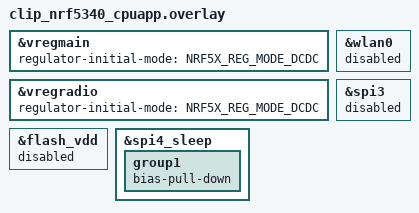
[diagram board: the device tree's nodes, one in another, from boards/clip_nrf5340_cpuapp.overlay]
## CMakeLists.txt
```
# SPDX-License-Identifier: Apache-2.0

cmake_minimum_required(VERSION 3.20.0)

find_package(Zephyr REQUIRED HINTS $ENV{ZEPHYR_BASE})

project(suspend_to_ram)

target_sources(app PRIVATE src/main.c)
```

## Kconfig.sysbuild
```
#
# SPDX-License-Identifier: Apache-2.0
#
# Sysbuild config — required for nRF5340 Bluetooth controller.
# Builds the cpunet child image with the BT HCI IPC firmware so the
# application core (cpuapp) can talk to the BLE controller over IPC.

source "${ZEPHYR_BASE}/share/sysbuild/Kconfig"

config NRF_DEFAULT_IPC_RADIO
	default y

config NETCORE_IPC_RADIO_BT_HCI_IPC
	default y
```

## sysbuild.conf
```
# SPDX-License-Identifier: Apache-2.0
#
# MCUboot sysbuild configuration
#
# Build: west build --build-dir build-<sample> --board clip/nrf5340/cpuapp samples/<sample>

# MCUboot bootloader
SB_CONFIG_BOOTLOADER_MCUBOOT=y

# External SPI flash for DFU secondary partition
SB_CONFIG_PM_EXTERNAL_FLASH_MCUBOOT_SECONDARY=y
SB_CONFIG_PM_OVERRIDE_EXTERNAL_DRIVER_CHECK=y

# Dual-image MCUboot (app + netcore)
SB_CONFIG_MCUBOOT_UPDATEABLE_IMAGES=2
SB_CONFIG_MCUBOOT_NRF53_MULTI_IMAGE_UPDATE=y
SB_CONFIG_NETCORE_APP_UPDATE=y

# Overwrite-only mode (no rollback)
SB_CONFIG_MCUBOOT_MODE_OVERWRITE_ONLY=y

# Network core IPC radio (required on nRF5340 dual-core)
SB_CONFIG_NETCORE_IPC_RADIO=y
SB_CONFIG_NETCORE_IPC_RADIO_BT_HCI_IPC=y

# Secure boot for network core
SB_CONFIG_SECURE_BOOT_NETCORE=y

# Signing key (must match the key used to build MCUboot on the device)
SB_CONFIG_BOOT_SIGNATURE_KEY_FILE="${APPLICATION_CONFIG_DIR}/sysbuild/root-rsa-2048.pem"
```

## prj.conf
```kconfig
# SPDX-License-Identifier: Apache-2.0
#
# PMIC + SoC suspend-to-RAM test for nRF5340 on reSpeaker Clip.
# No nRF7002 / WiFi stack (the wlan0 node is disabled in the overlay).
# BLE advertising is used as a suspend indicator.
# Builds under MCUboot like the other samples; the external SPI flash stays
# in the partition layout (mcuboot's secondary slot) but its driver/bus are
# disabled here and the rail is power-gated at runtime.

CONFIG_MAIN_STACK_SIZE=2048
CONFIG_HEAP_MEM_POOL_SIZE=0

# Power management
CONFIG_PM=y
CONFIG_PM_DEVICE=y
CONFIG_PM_DEVICE_RUNTIME=y
CONFIG_TICKLESS_KERNEL=y

# PMIC control (nPM1300) — rail power-gating
CONFIG_I2C=y
CONFIG_MFD=y
CONFIG_MFD_NPM13XX=y
CONFIG_REGULATOR=y
CONFIG_REGULATOR_NPM13XX=y

# Bluetooth Low Energy advertising (suspend indicator)
CONFIG_BT=y
CONFIG_BT_PERIPHERAL=y
CONFIG_BT_DEVICE_NAME="Clip"

# Indicator GPIO + console
CONFIG_GPIO=y
CONFIG_SERIAL=y
CONFIG_UART_CONSOLE=y
CONFIG_CONSOLE=y
CONFIG_LOG=y
CONFIG_LOG_DEFAULT_LEVEL=3

# SPI for SD card (SPI4)
CONFIG_SPI=y

# SD card + FAT filesystem
CONFIG_FILE_SYSTEM=y
CONFIG_FAT_FILESYSTEM_ELM=y
CONFIG_FS_FATFS_LFN=y
CONFIG_DISK_ACCESS=y
CONFIG_DISK_DRIVER_SDMMC=y

# Flash: keep the partition map (mcuboot slot layout) but no external SPI
# flash driver — the external flash bus/rail are disabled in the overlay.
CONFIG_FLASH=y
CONFIG_FLASH_MAP=y
CONFIG_SPI_NOR=n

# Disable unused reSpeaker Clip module defaults for this sample
CONFIG_OLED_DISPLAY=n
CONFIG_GPIO_BUTTON=n
CONFIG_SENSOR=n
CONFIG_INPUT=n
```

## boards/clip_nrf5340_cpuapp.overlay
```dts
/*
 * SPDX-License-Identifier: Apache-2.0
 *
 * Switch nRF5340 internal regulators from the SDK default LDO to DCDC.
 * The Clip board has 10µH inductors (L1, L2) wired for DCDC support.
 * Without this, suspend current is ~500-600 µA higher than the datasheet.
 *
 * Disable the nRF7002 WiFi node so its driver and the MPSL coexistence
 * service (which would otherwise keep HFXO running) are not pulled in.
 */

&vregmain {
	regulator-initial-mode = <NRF5X_REG_MODE_DCDC>;
};

&vregradio {
	regulator-initial-mode = <NRF5X_REG_MODE_DCDC>;
};

&wlan0 {
	status = "disabled";
};

/* Disable the external SPI flash bus and its power rail for the idle
 * current baseline. The external flash stays in the partition map (it is
 * mcuboot's secondary slot — mcuboot enables it in its own overlay), so do
 * NOT delete nordic,pm-ext-flash here or mcuboot fails to find its
 * secondary slot (PM_MCUBOOT_SECONDARY_ID undeclared). */
&spi3 {
	status = "disabled";
};

&flash_vdd {
	status = "disabled";
};

/*
 * Add pull-down to SPI4 sleep pinctrl so suspended pins don't float
 * and leak through the SD card's ESD diodes.
 */
&spi4_sleep {
	group1 {
		bias-pull-down;
	};
};
```

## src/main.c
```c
/*
 * SPDX-License-Identifier: Apache-2.0
 *
 * PM_STATE_SUSPEND_TO_RAM test for reSpeaker Clip (nRF5340) with the
 * peripheral rails turned off. No nRF7002 / MPSL / WiFi / BT stack.
 *
 * Tests SD card mount/unmount/poweroff in a loop every 30s to verify
 * current returns to ~250µA after each cycle.
 *
 * Measure with a Power Profiler Kit on the 3V3 rail.
 */

#include <zephyr/kernel.h>
#include <zephyr/logging/log.h>
#include <zephyr/pm/pm.h>
#include <zephyr/pm/device.h>
#include <zephyr/drivers/gpio.h>
#include <zephyr/drivers/regulator.h>
#include <zephyr/sys/__assert.h>
#include <zephyr/bluetooth/bluetooth.h>
#include <zephyr/bluetooth/hci.h>
#include <zephyr/dt-bindings/regulator/npm13xx.h>
#include <zephyr/storage/disk_access.h>
#include <zephyr/fs/fs.h>
#include <ff.h>

LOG_MODULE_REGISTER(suspend_to_ram, LOG_LEVEL_INF);

#define SUSPEND_INDICATE_PIN 15
#define SUSPEND_INDICATE_PORT gpio1
#define SPI4_CS_PIN          9  /* gpio0.9 - SD card CS (active-low) */

static const struct device *gpio0 = DEVICE_DT_GET(DT_NODELABEL(gpio0));
static const struct device *gpio1 = DEVICE_DT_GET(DT_NODELABEL(gpio1));
static const struct device *buck2 = DEVICE_DT_GET(DT_NODELABEL(npm1300_buck2));
static const struct device *ldo1  = DEVICE_DT_GET(DT_NODELABEL(npm1300_ldo1));
static const struct device *ldo2  = DEVICE_DT_GET(DT_NODELABEL(npm1300_ldo2));
static const struct device *spi4  = DEVICE_DT_GET(DT_NODELABEL(spi4));

static FATFS fat_fs;
static struct fs_mount_t mp = {
	.type = FS_FATFS,
	.fs_data = &fat_fs,
	.mnt_point = "/SD:",
};

static void on_pm_state_entry(enum pm_state state)
{
	if (state == PM_STATE_SUSPEND_TO_RAM) {
		gpio_pin_set(SUSPEND_INDICATE_PORT, SUSPEND_INDICATE_PIN, 1);
	}
}

static void on_pm_state_exit(enum pm_state state)
{
	ARG_UNUSED(state);
	gpio_pin_set(SUSPEND_INDICATE_PORT, SUSPEND_INDICATE_PIN, 0);
}

static struct pm_notifier notifier = {
	.state_entry = on_pm_state_entry,
	.state_exit = on_pm_state_exit,
};

/*
 * Suspend SPI4 so pinctrl applies the sleep state (pins disconnected +
 * pulled down). Also park CS as input+pull-down to prevent leakage
 * through the unpowered SD card's ESD diodes.
 */
static void spi4_suspend(void)
{
	gpio_pin_configure(gpio0, SPI4_CS_PIN, GPIO_INPUT | GPIO_PULL_DOWN);
	pm_device_action_run(spi4, PM_DEVICE_ACTION_SUSPEND);
	LOG_INF("SPI4 suspended (sleep pinctrl)");
}

/*
 * Resume SPI4 so pinctrl restores the default state (SCK/MOSI/MISO
 * back in SPIM function). Restore CS as output with GPIO_ACTIVE_LOW
 * preserved — physical HIGH = deselected.
 */
static void spi4_resume(void)
{
	pm_device_action_run(spi4, PM_DEVICE_ACTION_RESUME);
	gpio_pin_configure(gpio0, SPI4_CS_PIN,
			   GPIO_OUTPUT_HIGH | GPIO_ACTIVE_LOW);
	LOG_INF("SPI4 resumed (default pinctrl)");
}

static void shutdown_peripheral_rails(void)
{
	/* OLED_EN kept ON for display test */

	if (device_is_ready(ldo1)) {
		regulator_disable(ldo1);
		LOG_INF("LDO1 (mic) disabled");
	}
	if (device_is_ready(ldo2)) {
		regulator_disable(ldo2);
		LOG_INF("LDO2 (SD) disabled");
	}
	if (device_is_ready(buck2)) {
		/* PFM skipped for baseline test */
		LOG_INF("BUCK2 PFM skipped");
	}

	spi4_suspend();

	/* Park all SPI flash pins as input+pull-down to prevent leakage */
	static const uint8_t flash_pins[] = {19, 20, 21, 22, 23, 24};
	for (int i = 0; i < ARRAY_SIZE(flash_pins); i++) {
		gpio_pin_configure(gpio0, flash_pins[i],
				   GPIO_INPUT | GPIO_PULL_DOWN);
	}
	/* P0.27 flash VDD — drive low since regulator-fixed is disabled */
	gpio_pin_configure(gpio0, 27, GPIO_OUTPUT_INACTIVE);
	LOG_INF("Flash pins parked (P0.19-24 input+pd, P0.27 output low)");
}

static int test_sd_card(void)
{
	int rc;
	struct fs_statvfs stat;

	memset(&fat_fs, 0, sizeof(fat_fs));

	/* Power on SD card */
	if (device_is_ready(ldo2)) {
		regulator_enable(ldo2);
		k_msleep(100);
		LOG_INF("LDO2 (SD) enabled");
	}

	/* Restore SPI4 pins to SPI function */
	spi4_resume();

	rc = disk_access_init("SD");
	if (rc) {
		LOG_ERR("disk_access_init failed: %d", rc);
		goto power_off;
	}
	LOG_INF("SD disk initialized");

	rc = fs_mount(&mp);
	if (rc) {
		LOG_ERR("fs_mount failed: %d", rc);
		goto power_off;
	}
	LOG_INF("SD mounted");

	rc = fs_statvfs("/SD:", &stat);
	if (rc == 0) {
		LOG_INF("SD: %u MB free",
			(unsigned)(stat.f_bfree * stat.f_bsize / (1024 * 1024)));
	}

	struct fs_file_t file;

	fs_file_t_init(&file);
	rc = fs_open(&file, "/SD:/test_suspend.txt", FS_O_WRITE | FS_O_CREATE | FS_O_TRUNC);
	if (rc == 0) {
		fs_write(&file, "SD card test before suspend\n", 28);
		fs_close(&file);
		LOG_INF("Test file written");
	}

	rc = fs_unmount(&mp);
	if (rc) {
		LOG_ERR("fs_unmount failed: %d", rc);
		goto power_off;
	}
	LOG_INF("SD unmounted");

	disk_access_ioctl("SD", DISK_IOCTL_CTRL_DEINIT, NULL);
	LOG_INF("SD disk deinitialized");

	k_msleep(100);

power_off:
	if (device_is_ready(ldo2)) {
		regulator_disable(ldo2);
		LOG_INF("LDO2 (SD) disabled");
	}

	spi4_suspend();

	LOG_INF("SD card cycle complete");
	return rc;
}

static const struct bt_data ad[] = {
	BT_DATA_BYTES(BT_DATA_FLAGS, BT_LE_AD_GENERAL | BT_LE_AD_NO_BREDR),
	BT_DATA_BYTES(BT_DATA_NAME_COMPLETE, 'C', 'l', 'i', 'p'),
};

static void bt_ready(int err)
{
	if (err) {
		LOG_ERR("Bluetooth init failed: %d", err);
		return;
	}
	LOG_INF("Bluetooth initialized");

	err = bt_le_adv_start(BT_LE_ADV_NCONN, ad, ARRAY_SIZE(ad), NULL, 0);
	if (err) {
		LOG_ERR("Advertising failed: %d", err);
		return;
	}
	LOG_INF("Advertising as \"Clip\" started");
}

int main(void)
{
	if (!device_is_ready(gpio0) || !device_is_ready(gpio1)) {
		LOG_ERR("gpio not ready");
		return -1;
	}

	int ret = gpio_pin_configure(SUSPEND_INDICATE_PORT, SUSPEND_INDICATE_PIN, GPIO_OUTPUT_INACTIVE);

	if (ret != 0) {
		LOG_ERR("gpio_pin_configure failed: %d", ret);
		return -1;
	}

	shutdown_peripheral_rails();

	pm_notifier_register(&notifier);

	bt_enable(bt_ready);

	LOG_INF("=== suspend_to_ram ready (30s SD cycle) ===");
	LOG_INF("Probe GPIO1.%d: HIGH = in suspend-to-RAM.",
		SUSPEND_INDICATE_PIN);

	while (1) {
		LOG_INF("--- SD cycle start ---");
		test_sd_card();
		LOG_INF("--- SD cycle end, sleeping 30s ---");
		k_sleep(K_SECONDS(30));
	}

	return 0;
}
```
